# GUARDCHIP register map
Registers are 32-bit, read-write, no defined reset value unless marked. A register's access mark holds for its fields unless they carry their own. Offsets are from the block's base; lines under a group give offsets from that group; [hi:lo] are bit positions; {n}, {i} and the like mark numbered series; 'fields as' and 'values as' point back to an identical list; <NAME> marks a mode.

## Memory map
0x40001400 RTC
0x42000400 EVSYS
0x42002C00 TC

## TC
Base 0x42002C00
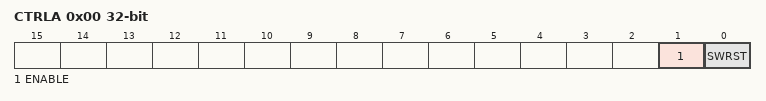
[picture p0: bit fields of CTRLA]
0x00 CTRLA
  [1] ENABLE, [0] SWRST wo

## RTC
Base 0x40001400
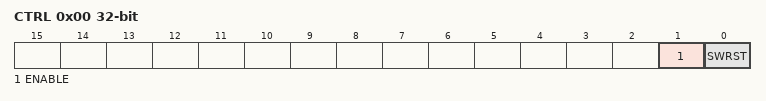
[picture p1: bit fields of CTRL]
0x00 CTRL
  [1] ENABLE, [0] SWRST wo

## EVSYS
Base 0x42000400
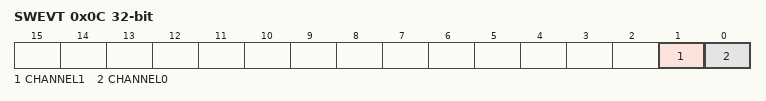
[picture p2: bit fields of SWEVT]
0x0C SWEVT
  [1] CHANNEL1 wo, [0] CHANNEL0 wo
